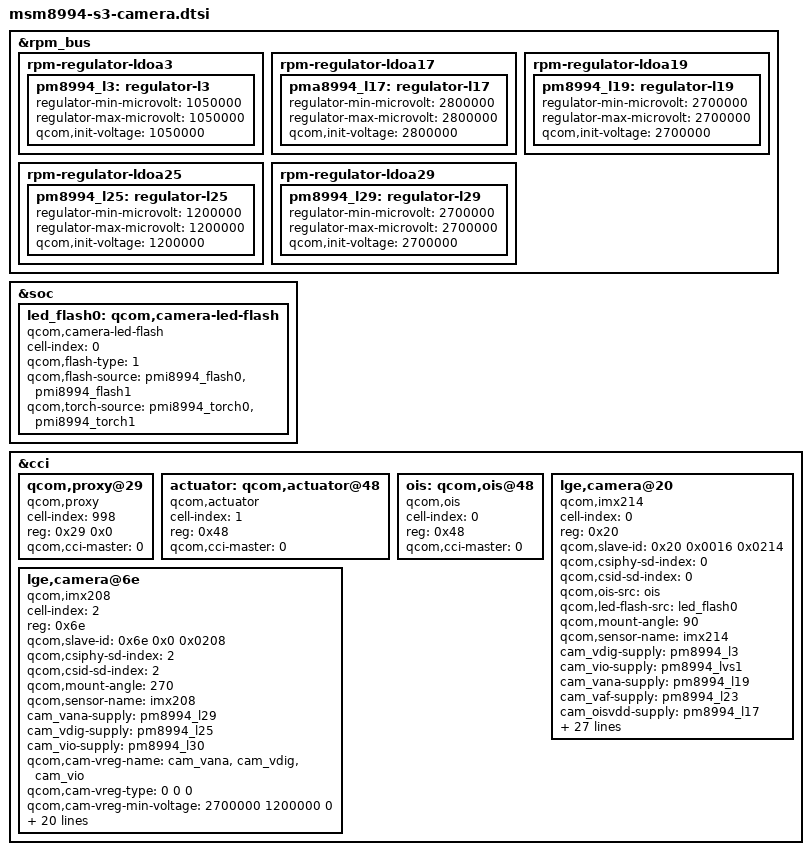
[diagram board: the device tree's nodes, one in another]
/* Copyright (c) 2014, The Linux Foundation. All rights reserved.
 *
 * This program is free software; you can redistribute it and/or modify
 * it under the terms of the GNU General Public License version 2 and
 * only version 2 as published by the Free Software Foundation.
 *
 * This program is distributed in the hope that it will be useful,
 * but WITHOUT ANY WARRANTY; without even the implied warranty of
 * MERCHANTABILITY or FITNESS FOR A PARTICULAR PURPOSE.  See the
 * GNU General Public License for more details.
 */

&rpm_bus {
	rpm-regulator-ldoa3 {
		status = "okay";
		pm8994_l3: regulator-l3 {
			regulator-min-microvolt = <1050000>;
			regulator-max-microvolt = <1050000>;
			qcom,init-voltage = <1050000>;
			status = "okay";
		};
	};

	rpm-regulator-ldoa17 {
		status = "okay";
		pma8994_l17: regulator-l17 {
			regulator-min-microvolt = <2800000>;
			regulator-max-microvolt = <2800000>;
			qcom,init-voltage = <2800000>;
			status = "okay";
		};
	};

	rpm-regulator-ldoa19 {
		status = "okay";
		pm8994_l19: regulator-l19 {
			regulator-min-microvolt = <2700000>;
			regulator-max-microvolt = <2700000>;
			qcom,init-voltage = <2700000>;
			status = "okay";
		};
	};

	rpm-regulator-ldoa25 {
		status = "okay";
		pm8994_l25: regulator-l25 {
			regulator-min-microvolt = <1200000>;
			regulator-max-microvolt = <1200000>;
			qcom,init-voltage = <1200000>;
			status = "okay";
		};
	};

	rpm-regulator-ldoa29 {
		status = "okay";
		pm8994_l29: regulator-l29 {
			regulator-min-microvolt = <2700000>;
			regulator-max-microvolt = <2700000>;
			qcom,init-voltage = <2700000>;
			status = "okay";
		};
	};
};

&soc {
	led_flash0: qcom,camera-led-flash {
		cell-index = <0>;
		compatible = "qcom,camera-led-flash";
		qcom,flash-type = <1>;
		qcom,flash-source = <&pmi8994_flash0 &pmi8994_flash1>;
		qcom,torch-source = <&pmi8994_torch0 &pmi8994_torch1>;
	};
};

&cci {
	qcom,proxy@29 {
		cell-index = <998>;
		reg = <0x29 0x0>;
		compatible = "qcom,proxy";
		qcom,cci-master = <0>;
	};

	actuator: qcom,actuator@48 {
		cell-index = <1>;
		reg = <0x48>;
		compatible = "qcom,actuator";
		qcom,cci-master = <0>;
		/*cam_vaf-supply = <&pm8994_l23>;
		qcom,cam-vreg-name = "cam_vaf";
		qcom,cam-vreg-type = <0>;
		qcom,cam-vreg-min-voltage = <2800000>;
		qcom,cam-vreg-max-voltage = <2800000>;
		qcom,cam-vreg-op-mode = <100000>;*/
	};

	ois: qcom,ois@48 {
		cell-index = <0>;
		reg = <0x48>;
		compatible = "qcom,ois";
		qcom,cci-master = <0>;
		/*cam_oisvdd-supply = <&pm8994_l17>;
		qcom,cam-vreg-name = "cam_oisvdd";
		qcom,cam-vreg-type = <0>;
		qcom,cam-vreg-min-voltage = <2800000>;
		qcom,cam-vreg-max-voltage = <2800000>;
		qcom,cam-vreg-op-mode = <100000>;*/
	};
/*
	eeprom: qcom,eeprom@a0 {
		cell-index = <0>;
		reg = <0xa0 0x0>;
		qcom,eeprom-name = "imx214_eeprom";
		compatible = "qcom,eeprom";
		qcom,slave-addr = <0xa0>;
		qcom,cci-master = <0>;
		qcom,num-blocks = <1>;
		qcom,page0 = <0 0x0 2 0x0 1 20>;
		qcom,poll0 = <0 0x0 2 0x0 1 20>;
		qcom,mem0 = <0x900 0x0000 2 0 1 0>;
		cam_vdig-supply = <&pm8994_l3>;
		cam_vio-supply = <&pm8994_lvs1>;
		cam_vana-supply = <&pm8994_l19>;
		cam_vaf-supply = <&pm8994_l23>;
		cam_oisvdd-supply = <&pm8994_l17>;
		qcom,cam-vreg-name = "cam_vdig", "cam_vio", "cam_vana", "cam_vaf", "cam_oisvdd";
		qcom,cam-vreg-type = <0 0 0 0 0>;
		qcom,cam-vreg-min-voltage = <1050000 0 2700000 2800000 2800000>;
		qcom,cam-vreg-max-voltage = <1050000 0 2700000 2800000 2800000>;
		qcom,cam-vreg-op-mode = <1050000 0 100000 100000 100000>;
		qcom,gpio-no-mux = <0>;

		gpios = <&msm_gpio 13 0>,	//MCLK
			<&msm_gpio 92 0>;	// MAIN_CAM0_RESET_N
		qcom,gpio-reset = <1>;
		qcom,gpio-req-tbl-num = <0 1>;
		qcom,gpio-req-tbl-flags = <0 0>;
		qcom,gpio-req-tbl-label = "CAMIF_MCLK0",
								"MAIN_CAM_RESET";
		qcom,cam-power-seq-type = "sensor_gpio", "sensor_vreg", "sensor_vreg", "sensor_vreg",
						"sensor_vreg", "sensor_vreg", "sensor_clk", "sensor_gpio";
		qcom,cam-power-seq-val = "sensor_gpio_reset", "cam_vana", "cam_vdig", "cam_vio",
						"cam_vaf", "cam_oisvdd"  ,"sensor_cam_mclk", "sensor_gpio_reset";
		qcom,cam-power-seq-cfg-val = <0 1 1 1 1 1 24000000 1>;
		qcom,cam-power-seq-delay = <1 1 1 5 1 1 50 50>;
		clocks = <&clock_mmss clk_mclk0_clk_src>,
				<&clock_mmss clk_camss_mclk0_clk>;
		clock-names = "cam_src_clk", "cam_clk";
	};
*/
	lge,camera@20 {
		cell-index = <0>;
		compatible = "qcom,imx214";
		reg = <0x20>;
		qcom,slave-id = <0x20 0x0016 0x0214>;
		qcom,csiphy-sd-index = <0>;
		qcom,csid-sd-index = <0>;
		//qcom,actuator-src = <&actuator>;
		qcom,ois-src = <&ois>;
		//qcom,eeprom-src = <&eeprom>;
		qcom,led-flash-src = <&led_flash0>;
		qcom,mount-angle = <90>;
		qcom,sensor-name = "imx214";
		cam_vdig-supply = <&pm8994_l3>;
		cam_vio-supply = <&pm8994_lvs1>;
		cam_vana-supply = <&pm8994_l19>;
		cam_vaf-supply = <&pm8994_l23>;
		cam_oisvdd-supply = <&pm8994_l17>;
		qcom,cam-vreg-name = "cam_vdig", "cam_vio", "cam_vana", "cam_vaf", "cam_oisvdd";
		qcom,cam-vreg-type = <0 0 0 0 0>;
		qcom,cam-vreg-min-voltage = <1050000 0 2700000 2800000 2800000>;
		qcom,cam-vreg-max-voltage = <1050000 0 2700000 2800000 2800000>;
		qcom,cam-vreg-op-mode = <1050000 0 100000 100000 100000>;
		qcom,gpio-no-mux = <0>;
		pinctrl-names = "cam_default", "cam_suspend";
		pinctrl-0 = <&cam_sensor_mclk0_active &cam_sensor_rear_active>;
		pinctrl-1 = <&cam_sensor_mclk0_suspend &cam_sensor_rear_suspend>;
		gpios = <&msm_gpio 13 0>,	//MCLK
			<&msm_gpio 92 0>;	// MAIN_CAM0_RESET_N
		qcom,gpio-reset = <1>;
		qcom,gpio-req-tbl-num = <0 1>;
		qcom,gpio-req-tbl-flags = <0 0>;
		qcom,gpio-req-tbl-label = "CAMIF_MCLK0",
								"MAIN_CAM_RESET";
		qcom,csi-lane-assign = <0x4320>;
		qcom,csi-lane-mask = <0x1F>;
		qcom,sensor-position = <0>;
		qcom,sensor-mode = <0>;
		qcom,cci-master = <0>;
		status = "ok";
		clocks = <&clock_mmss clk_mclk0_clk_src>,
				<&clock_mmss clk_camss_mclk0_clk>;
		clock-names = "cam_src_clk", "cam_clk";
	};

	lge,camera@6e {
		cell-index = <2>;
		compatible = "qcom,imx208";
		reg = <0x6e>;
		qcom,slave-id = <0x6e 0x0 0x0208>;
		qcom,csiphy-sd-index = <2>;
		qcom,csid-sd-index = <2>;
		qcom,mount-angle = <270>;
		qcom,sensor-name = "imx208";
		cam_vana-supply = <&pm8994_l29>;
		cam_vdig-supply = <&pm8994_l25>;
		cam_vio-supply = <&pm8994_l30>;
		qcom,cam-vreg-name =  "cam_vana", "cam_vdig", "cam_vio";
		qcom,cam-vreg-type = <0 0 0>;
		qcom,cam-vreg-min-voltage = <2700000 1200000 0>;
		qcom,cam-vreg-max-voltage = <2700000 1200000 0>;
		qcom,cam-vreg-op-mode = <80000 105000 0>;
		qcom,gpio-no-mux = <0>;
		pinctrl-names = "cam_default", "cam_suspend";
		pinctrl-0 = <&cam_sensor_mclk2_active &cam_sensor_front_active>;
		pinctrl-1 = <&cam_sensor_mclk2_suspend &cam_sensor_front_suspend>;
		gpios = <&msm_gpio 15 0>,
			<&msm_gpio 104 0>;
		qcom,gpio-reset = <1>;
		qcom,gpio-req-tbl-num = <0 1>;
		qcom,gpio-req-tbl-flags = <0 0>;
		qcom,gpio-req-tbl-label = "CAMIF_MCLK2",
								"CAM_RESET2";
		qcom,csi-lane-assign = <0x4320>;
		qcom,csi-lane-mask = <0x3>;
		qcom,sensor-position = <1>;
		qcom,sensor-mode = <1>;
		qcom,cci-master = <1>;
		status = "ok";
		clocks = <&clock_mmss clk_mclk2_clk_src>,
			<&clock_mmss clk_camss_mclk2_clk>;
		clock-names = "cam_src_clk", "cam_clk";
	};
};
